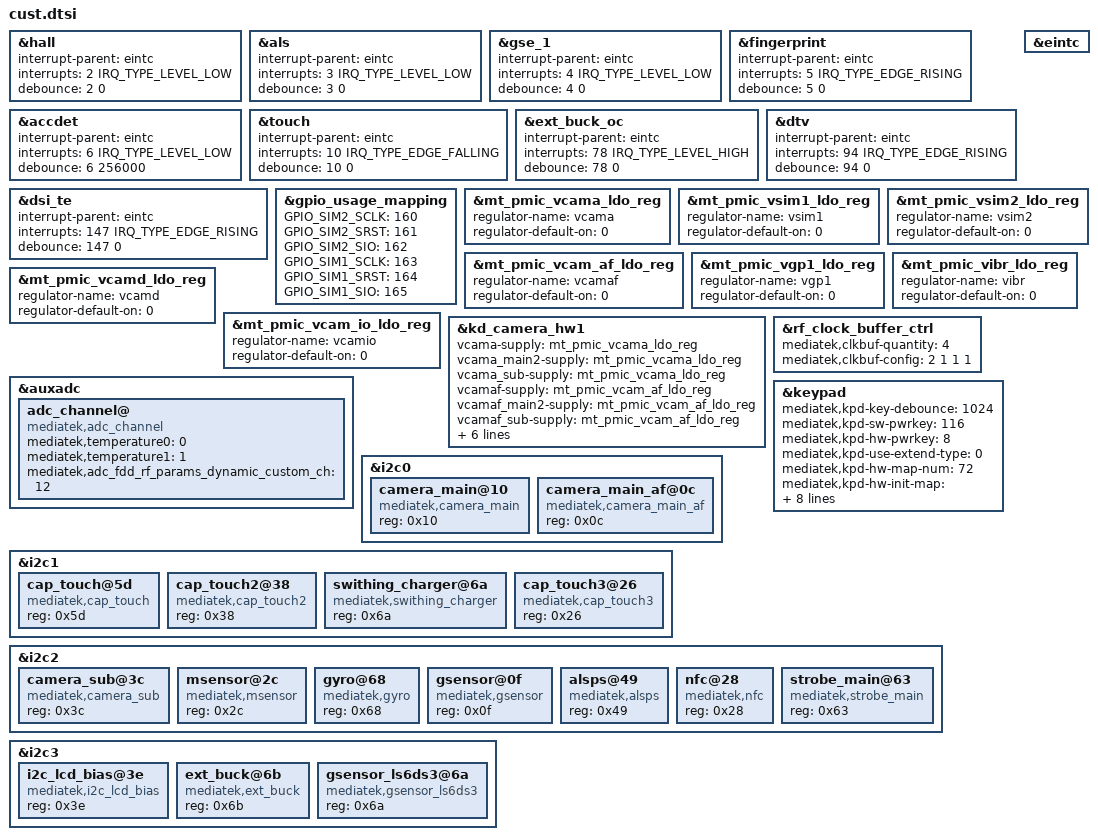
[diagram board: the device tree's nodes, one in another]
/*
 * Generated by MTK SP Drv_CodeGen Version 03.13.6  for MT6735M. Copyright MediaTek Inc. (C) 2013.
 * Tue Nov 28 19:19:58 2017
 * Do Not Modify the File.
 */

#include <dt-bindings/interrupt-controller/irq.h>
#include <dt-bindings/interrupt-controller/arm-gic.h>

/*************************
 * EINT DTSI File
*************************/

&hall {
	interrupt-parent = <&eintc>;
	interrupts = <2 IRQ_TYPE_LEVEL_LOW>;
	debounce = <2 0>;
	status = "okay";
};
&als {
	interrupt-parent = <&eintc>;
	interrupts = <3 IRQ_TYPE_LEVEL_LOW>;
	debounce = <3 0>;
	status = "okay";
};
&gse_1 {
	interrupt-parent = <&eintc>;
	interrupts = <4 IRQ_TYPE_LEVEL_LOW>;
	debounce = <4 0>;
	status = "okay";
};
&fingerprint {
	interrupt-parent = <&eintc>;
	interrupts = <5 IRQ_TYPE_EDGE_RISING>;
	debounce = <5 0>;
	status = "okay";
};
&accdet {
	interrupt-parent = <&eintc>;
	interrupts = <6 IRQ_TYPE_LEVEL_LOW>;
	debounce = <6 256000>;
	status = "okay";
};
&touch {
	interrupt-parent = <&eintc>;
	interrupts = <10 IRQ_TYPE_EDGE_FALLING>;
	debounce = <10 0>;
	status = "okay";
};
&ext_buck_oc {
	interrupt-parent = <&eintc>;
	interrupts = <78 IRQ_TYPE_LEVEL_HIGH>;
	debounce = <78 0>;
	status = "okay";
};
&dtv {
	interrupt-parent = <&eintc>;
	interrupts = <94 IRQ_TYPE_EDGE_RISING>;
	debounce = <94 0>;
	status = "okay";
};
&dsi_te {
	interrupt-parent = <&eintc>;
	interrupts = <147 IRQ_TYPE_EDGE_RISING>;
	debounce = <147 0>;
	status = "okay";
};


/********************
 * GPIO USAGE MAPPING DTSI File
****************/

&gpio_usage_mapping {
	GPIO_SIM2_SCLK = <160>;
	GPIO_SIM2_SRST = <161>;
	GPIO_SIM2_SIO = <162>;
	GPIO_SIM1_SCLK = <163>;
	GPIO_SIM1_SRST = <164>;
	GPIO_SIM1_SIO = <165>;
};


&eintc {
};


/*************************
 * PMIC DTSI File
*************************/

&mt_pmic_vcama_ldo_reg {
	regulator-name = "vcama";
	regulator-default-on = <0>; /* 0:skip, 1: off, 2:on */
	status = "okay";
};
&mt_pmic_vsim1_ldo_reg {
	regulator-name = "vsim1";
	regulator-default-on = <0>; /* 0:skip, 1: off, 2:on */
	status = "okay";
};
&mt_pmic_vsim2_ldo_reg {
	regulator-name = "vsim2";
	regulator-default-on = <0>; /* 0:skip, 1: off, 2:on */
	status = "okay";
};
&mt_pmic_vcam_af_ldo_reg {
	regulator-name = "vcamaf";
	regulator-default-on = <0>; /* 0:skip, 1: off, 2:on */
	status = "okay";
};
&mt_pmic_vgp1_ldo_reg {
	regulator-name = "vgp1";
	regulator-default-on = <0>; /* 0:skip, 1: off, 2:on */
	status = "okay";
};
&mt_pmic_vibr_ldo_reg {
	regulator-name = "vibr";
	regulator-default-on = <0>; /* 0:skip, 1: off, 2:on */
	status = "okay";
};
&mt_pmic_vcamd_ldo_reg {
	regulator-name = "vcamd";
	regulator-default-on = <0>; /* 0:skip, 1: off, 2:on */
	status = "okay";
};
&mt_pmic_vcam_io_ldo_reg {
	regulator-name = "vcamio";
	regulator-default-on = <0>; /* 0:skip, 1: off, 2:on */
	status = "okay";
};

&kd_camera_hw1 {
	vcama-supply = <&mt_pmic_vcama_ldo_reg>;
	vcama_main2-supply = <&mt_pmic_vcama_ldo_reg>;
	vcama_sub-supply = <&mt_pmic_vcama_ldo_reg>;

	vcamaf-supply = <&mt_pmic_vcam_af_ldo_reg>;
	vcamaf_main2-supply = <&mt_pmic_vcam_af_ldo_reg>;
	vcamaf_sub-supply = <&mt_pmic_vcam_af_ldo_reg>;

	vcamd_main2-supply = <&mt_pmic_vgp1_ldo_reg>;
	vcamd_sub-supply = <&mt_pmic_vgp1_ldo_reg>;

	vcamd-supply = <&mt_pmic_vcamd_ldo_reg>;

	vcamio-supply = <&mt_pmic_vcam_io_ldo_reg>;
	vcamio_main2-supply = <&mt_pmic_vcam_io_ldo_reg>;
	vcamio_sub-supply = <&mt_pmic_vcam_io_ldo_reg>;

	status = "okay";
};

&touch {
	status = "okay";
};


/********************************************
 *ADC DTSI File
********************************************/

&auxadc {
	adc_channel@ {
		compatible = "mediatek,adc_channel";
		mediatek,temperature0 = <0>;
		mediatek,temperature1 = <1>;
		mediatek,adc_fdd_rf_params_dynamic_custom_ch = <12>;
		status = "okay";
	};
};


/**********************************************
 *CLK_BUF DTSI File
********************************************/

&rf_clock_buffer_ctrl {
	mediatek,clkbuf-quantity = <4>;
	mediatek,clkbuf-config = <2 1 1 1>;
	status = "okay";
};


/**********************************************
 *Keypad DTSI File
********************************************/

&keypad{
	mediatek,kpd-key-debounce = <1024>;
	mediatek,kpd-sw-pwrkey = <116>;
	mediatek,kpd-hw-pwrkey = <8>;
	mediatek,kpd-use-extend-type = <0>;
	/*HW Keycode [0~71] -> Linux Keycode*/
	mediatek,kpd-hw-map-num = <72>;
	mediatek,kpd-hw-init-map = <114 115 0 0 0 0 0 0 0 0 0 0 0 0 0 0 0 0 0 0 0 0 0 0 
				0 0 0 0 0 0 0 0 0 0 0 0 0 0 0 0 0 0 0 0 0 0 0 0 
				0 0 0 0 0 0 0 0 0 0 0 0 0 0 0 0 0 0 0 0 0 0 0 0 >;
	mediatek,kpd-pwrkey-eint-gpio = <0>;
	mediatek,kpd-pwkey-gpio-din  = <0>;
	mediatek,kpd-hw-dl-key0 = <1>;
	mediatek,kpd-hw-dl-key1 = <0>;
	mediatek,kpd-hw-dl-key2 = <8>;
	mediatek,kpd-hw-recovery-key = <1>;
	mediatek,kpd-hw-factory-key = <0>;
	status = "okay";
};


/*************************
 * I2C DTSI File
*************************/

&i2c0 {
	#address-cells = <1>;
	#size-cells = <0>;
	camera_main@10 {
		compatible = "mediatek,camera_main";
		reg = <0x10>;
		status = "okay";
	};
	camera_main_af@0c {
		compatible = "mediatek,camera_main_af";
		reg = <0x0c>;
		status = "okay";
	};
};

&i2c1 {
	#address-cells = <1>;
	#size-cells = <0>;
	cap_touch@5d {
		compatible = "mediatek,cap_touch";
		reg = <0x5d>;
		status = "okay";
	};
	cap_touch2@38 {
		compatible = "mediatek,cap_touch2";
		reg = <0x38>;
		status = "okay";
	};
	swithing_charger@6a {
		compatible = "mediatek,swithing_charger";
		reg = <0x6a>;
		status = "okay";
	};
	cap_touch3@26 {
		compatible = "mediatek,cap_touch3";
		reg = <0x26>;
		status = "okay";
	};
};

&i2c2 {
	#address-cells = <1>;
	#size-cells = <0>;
	camera_sub@3c {
		compatible = "mediatek,camera_sub";
		reg = <0x3c>;
		status = "okay";
	};
	msensor@2c {
		compatible = "mediatek,msensor";
		reg = <0x2c>;
		status = "okay";
	};
	gyro@68 {
		compatible = "mediatek,gyro";
		reg = <0x68>;
		status = "okay";
	};
	gsensor@0f {
		compatible = "mediatek,gsensor";
		reg = <0x0f>;
		status = "okay";
	};
	alsps@49 {
		compatible = "mediatek,alsps";
		reg = <0x49>;
		status = "okay";
	};
	nfc@28 {
		compatible = "mediatek,nfc";
		reg = <0x28>;
		status = "okay";
	};
	strobe_main@63 {
		compatible = "mediatek,strobe_main";
		reg = <0x63>;
		status = "okay";
	};
};

&i2c3 {
	#address-cells = <1>;
	#size-cells = <0>;
	i2c_lcd_bias@3e {
		compatible = "mediatek,i2c_lcd_bias";
		reg = <0x3e>;
		status = "okay";
	};
	ext_buck@6b {
		compatible = "mediatek,ext_buck";
		reg = <0x6b>;
		status = "okay";
	};
	gsensor_ls6ds3@6a {
		compatible = "mediatek,gsensor_ls6ds3";
		reg = <0x6a>;
		status = "okay";
	};
};



